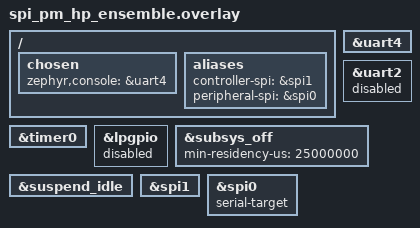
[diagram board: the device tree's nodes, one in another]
/* Copyright (C) Alif Semiconductor - All Rights Reserved.
 * Use, distribution and modification of this code is permitted under the
 * terms stated in the Alif Semiconductor Software License Agreement
 *
 * You should have received a copy of the Alif Semiconductor Software
 * License Agreement with this file. If not, please write to:
 * contact@alifsemi.com, or visit: https://alifsemi.com/license
 *
 * For SPI controller CS as:
 * - H/W controlled (default):
 *   - use CS pinmux as H/W
 *     - example for SPI1 as controller "PIN_P6_4__SPI1_SS0_B"
 *  "OR"
 * - S/W controlled using gpio:
 *   - use CS pinmux as gpio
 *     - example for SPI1 as controller "PIN_P6_4__GPIO"
 *   - define cs-gpios property
 *     - example for SPI1 as controller
 *        cs-gpios = <&gpio6 4 GPIO_ACTIVE_LOW>;
 */

/* Use timer0 as wakeup source instead */

&timer0 {
	status = "okay";
};

&lpgpio {
	status = "disabled";
};

&uart4 {
	status = "okay";
};

&uart2 {
	status = "disabled";
};

&subsys_off {
	min-residency-us = <25000000>;
	status = "okay";
};

&suspend_idle {
	status = "okay";
};

/ {
	chosen {
		zephyr,console = &uart4;
	};
};

/* default SPI controller CS is H/W controlled,
 * enable this to use as S/W controlled using gpio.
 */
#define SPI_CONTROLLER_CS_SW_CONTROLLED_GPIO 0

/ {
	aliases {
		controller-spi = &spi1;
		peripheral-spi = &spi0;
	};
};

&spi1 {
	status = "okay";

#if SPI_CONTROLLER_CS_SW_CONTROLLED_GPIO
	cs-gpios = <&gpio6 4 GPIO_ACTIVE_LOW>;
	/* as we are testing Loopback on the same board,
	 * make sure controller interrupt priority is
	 * higher than peripheral interrupt priority.
	 */
	interrupts = <138 0>;
#endif /* SPI_CONTROLLER_CS_SW_CONTROLLED_GPIO */
};

#if SPI_CONTROLLER_CS_SW_CONTROLLED_GPIO
/* use SPI1 master CS pinmux as gpio. */
&pinctrl_spi1 {
	group0 {
		pinmux = < PIN_P8_3__SPI1_MISO_B >,
			 < PIN_P8_4__SPI1_MOSI_B >,
			 < PIN_P8_5__SPI1_SCLK_B >,
			 < PIN_P6_4__GPIO >;
		read-enable = < 0x1 >;
	};
};

&gpio6 {
	status = "okay";
};
#endif /* SPI_CONTROLLER_CS_SW_CONTROLLED_GPIO */

&spi0 {
	status = "okay";
	serial-target;

#if SPI_CONTROLLER_CS_SW_CONTROLLED_GPIO
	interrupts = <137 1>;
#endif
};
